BO_ 21 NEW_MSG_15: 8 XXX

BO_ 22 PSCM: 8 XXX
 SG_ PSCM_ANGLE_SENSOR : 6|15@0- (1,0) [0|32767] "" XXX

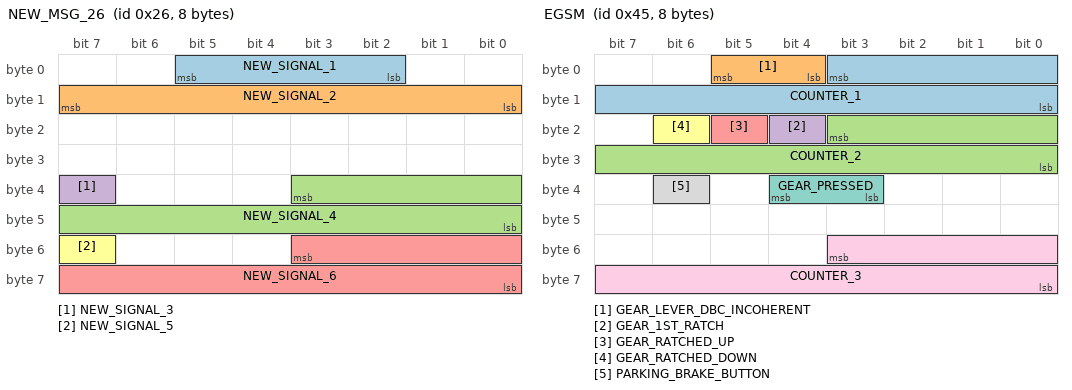
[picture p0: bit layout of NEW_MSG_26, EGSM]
BO_ 38 NEW_MSG_26: 8 XXX
 SG_ NEW_SIGNAL_1 : 5|4@0+ (1,0) [0|15] "" XXX
 SG_ NEW_SIGNAL_2 : 15|8@0+ (1,0) [0|255] "" XXX
 SG_ NEW_SIGNAL_4 : 35|12@0+ (1,0) [0|4095] "" XXX
 SG_ NEW_SIGNAL_3 : 39|1@0+ (1,0) [0|1] "" XXX
 SG_ NEW_SIGNAL_6 : 51|12@0+ (1,0) [0|4095] "" XXX
 SG_ NEW_SIGNAL_5 : 55|1@0+ (1,0) [0|1] "" XXX

BO_ 69 EGSM: 8 XXX
 SG_ COUNTER_1 : 3|12@0+ (1,0) [0|4095] "" XXX
 SG_ GEAR_LEVER_DBC_INCOHERENT : 5|2@0+ (1,0) [0|3] "" XXX
 SG_ COUNTER_2 : 19|12@0+ (1,0) [0|4095] "" XXX
 SG_ GEAR_1ST_RATCH : 20|1@0+ (1,0) [0|1] "" XXX
 SG_ GEAR_RATCHED_UP : 21|1@0+ (1,0) [0|1] "" XXX
 SG_ GEAR_RATCHED_DOWN : 22|1@0+ (1,0) [0|1] "" XXX
 SG_ GEAR_PRESSED : 36|2@0+ (1,0) [0|3] "" XXX
 SG_ PARKING_BRAKE_BUTTON : 38|1@0+ (1,0) [0|1] "" XXX
 SG_ COUNTER_3 : 51|12@0+ (1,0) [0|4095] "" XXX

BO_ 85 SAS: 8 XXX
 SG_ SAS_DRAFT : 14|23@0+ (1,0) [0|8388607] "" XXX

BO_ 87 NEW_MSG_57: 8 XXX

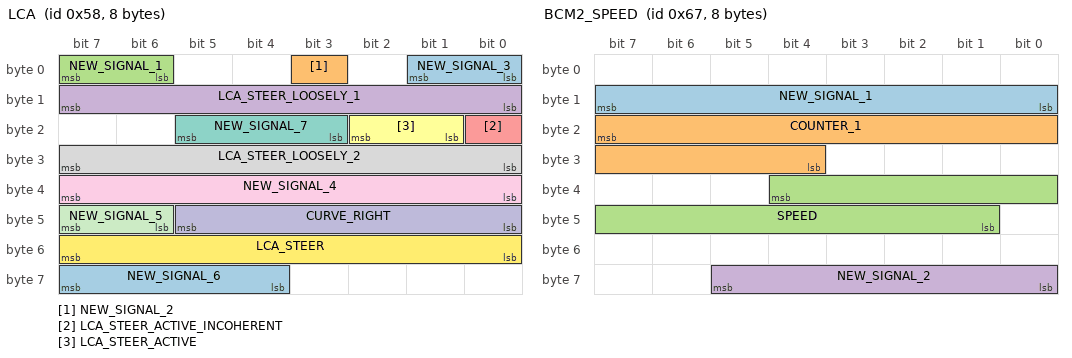
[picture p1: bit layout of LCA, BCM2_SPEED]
BO_ 88 LCA: 8 XXX
 SG_ NEW_SIGNAL_3 : 1|2@0+ (1,0) [0|3] "" XXX
 SG_ NEW_SIGNAL_2 : 3|1@0+ (1,0) [0|1] "" XXX
 SG_ NEW_SIGNAL_1 : 7|2@0+ (1,0) [0|3] "" XXX
 SG_ LCA_STEER_LOOSELY_1 : 15|8@0+ (1,0) [0|255] "" XXX
 SG_ LCA_STEER_ACTIVE_INCOHERENT : 16|1@0+ (1,0) [0|1] "" XXX
 SG_ LCA_STEER_ACTIVE : 18|2@0+ (1,0) [0|3] "" XXX
 SG_ NEW_SIGNAL_7 : 21|3@0+ (1,0) [0|7] "" XXX
 SG_ LCA_STEER_LOOSELY_2 : 31|8@0+ (1,0) [0|255] "" XXX
 SG_ NEW_SIGNAL_4 : 39|8@0+ (1,0) [0|255] "" XXX
 SG_ CURVE_RIGHT : 45|6@0+ (1,0) [0|63] "" XXX
 SG_ NEW_SIGNAL_5 : 46|2@1+ (1,0) [0|3] "" XXX
 SG_ LCA_STEER : 55|8@0- (1,0) [0|255] "" XXX
 SG_ NEW_SIGNAL_6 : 60|4@1+ (1,0) [0|15] "" XXX

BO_ 103 BCM2_SPEED: 8 XXX
 SG_ NEW_SIGNAL_1 : 8|8@1+ (1,0) [0|255] "" XXX
 SG_ COUNTER_1 : 23|12@0+ (1,0) [0|4095] "" XXX
 SG_ SPEED : 36|12@0+ (0.01,0) [0|4095] "m/s" XXX
 SG_ NEW_SIGNAL_2 : 61|6@0+ (1,0) [0|63] "" XXX

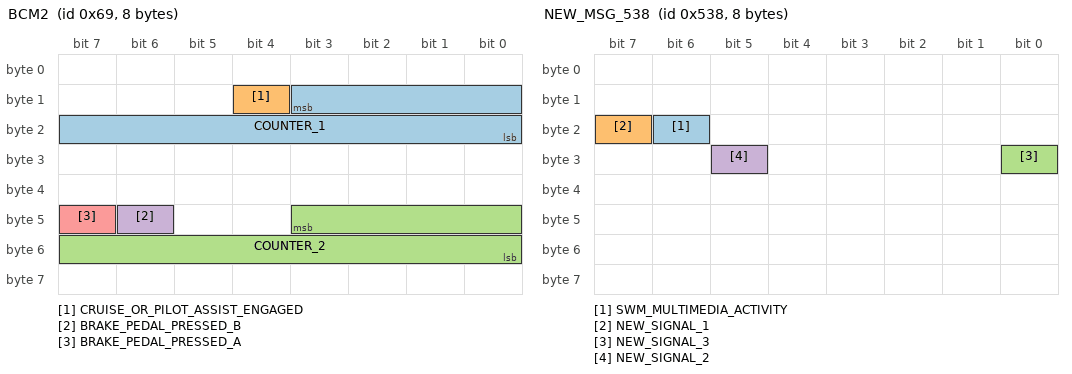
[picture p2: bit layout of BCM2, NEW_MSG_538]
BO_ 105 BCM2: 8 XXX
 SG_ COUNTER_1 : 11|12@0+ (1,0) [0|4095] "" XXX
 SG_ CRUISE_OR_PILOT_ASSIST_ENGAGED : 12|1@0+ (1,0) [0|1] "" XXX
 SG_ COUNTER_2 : 43|12@0+ (1,0) [0|4095] "" XXX
 SG_ BRAKE_PEDAL_PRESSED_B : 46|1@0+ (1,0) [0|1] "" XXX
 SG_ BRAKE_PEDAL_PRESSED_A : 47|1@0+ (-1,1) [0|1] "" XXX

BO_ 144 DRIVER_TORQUE: 8 XXX
 SG_ DRIVER_TORQUE : 39|16@0- (0.01,0) [0|65535] "" XXX

BO_ 151 EPS_TORQUE: 8 XXX
 SG_ EPS_TORQUE : 7|16@0- (0.01,0) [0|65535] "" XXX

BO_ 128 GEAR_POSITION: 8 XXX
 SG_ GEAR_POSITION : 57|2@0+ (1,0) [0|3] "" XXX

BO_ 336 NEW_MSG_150: 8 XXX
 SG_ IGN_DRAFT : 5|2@0+ (1,0) [0|3] "" XXX

BO_ 1336 NEW_MSG_538: 8 XXX
 SG_ SWM_MULTIMEDIA_ACTIVITY : 22|1@0+ (1,0) [0|1] "" XXX
 SG_ NEW_SIGNAL_1 : 23|1@0+ (1,0) [0|1] "" XXX
 SG_ NEW_SIGNAL_3 : 24|1@0+ (1,0) [0|1] "" XXX
 SG_ NEW_SIGNAL_2 : 29|1@0+ (1,0) [0|1] "" XXX

CM_ SG_ 88 CURVE_RIGHT "Only appears to be HIGH on curve right, LOW curve left";
CM_ SG_ 88 LCA_STEER "Seems torque-based, signed, follows the road curvature";
CM_ SG_ 144 DRIVER_TORQUE "DRAFT TODO: CHECK";
CM_ SG_ 151 EPS_TORQUE "DRAFT TODO: CHECK";
